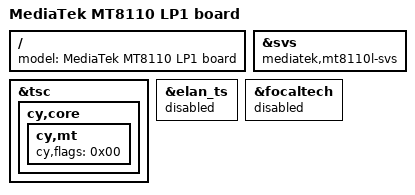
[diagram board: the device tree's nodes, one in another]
/*
 * Copyright (c) 2019 MediaTek Inc.
 *
 * SPDX-License-Identifier: (GPL-2.0 OR MIT)
 */

#include "aud8113tp1-E60T00-D0x00-base.dts"

/ {
	model = "MediaTek MT8110 LP1 board";
};

&svs {
   compatible = "mediatek,mt8110l-svs";
};



&cpu1 {
       status = "disabled";
};
/delete-node/ &cpu1;
/delete-node/ &{/cpus/cpu-map/cluster0/core1};



&tsc {
	status = "ok";
	cy,core {
		cy,mt {
			/* CY_MT_FLAG_FLIP | CY_MT_FLAG_INV_X | CY_MT_FLAG_INV_Y */
			cy,flags = <0x00>;
		};
	};
};
&elan_ts {
	status = "disabled";
};
&focaltech{
	status = "disabled";
};


/*
		cfa_panel 0: B/W, 1: cfa 
		cfa_rotate 1:rotate 90, 2:rotate 180 , 3:rotate 270
*/
/*
&hwtcon {
	epd{
		cfa_panel = <0>;		
		cfa_rotate = <0>;
	};
};
*/


